# ATxmega256C3 device description
Architecture: AVR8_XMEGA; Family: AVR XMEGA
Registers are 8-bit, access not given, no defined reset value unless marked. A register's access mark holds for its fields unless they carry their own. Offsets are from the block's base; [hi:lo] are bit positions; {n}, {i} and the like mark numbered series; 'fields as' and 'values as' point back to an identical list.

## OSC — Oscillator
Instances: OSC 0x0050
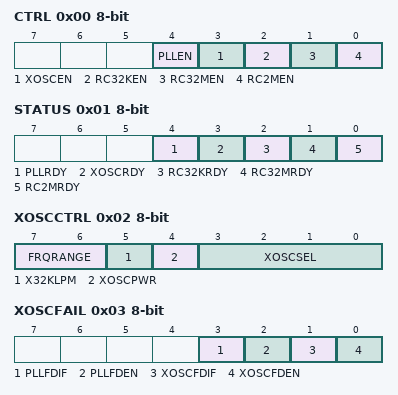
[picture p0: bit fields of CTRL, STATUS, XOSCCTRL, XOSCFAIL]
0x00 CTRL — Control Register
  [4] PLLEN — PLL Enable
  [3] XOSCEN — External Oscillator Enable
  [2] RC32KEN — Internal 32.768 kHz RC Oscillator Enable
  [1] RC32MEN — Internal 32 MHz RC Oscillator Enable
  [0] RC2MEN — Internal 2 MHz RC Oscillator Enable
0x01 STATUS
  [4] PLLRDY — PLL Ready
  [3] XOSCRDY — External Oscillator Ready
  [2] RC32KRDY — Internal 32.768 kHz RC Oscillator Ready
  [1] RC32MRDY — Internal 32 MHz RC Oscillator Ready
  [0] RC2MRDY — Internal 2 MHz RC Oscillator Ready
0x02 XOSCCTRL — External Oscillator Control Register
  [7:6] FRQRANGE — Frequency Range
    0=04TO2 (0.4 - 2 MHz); 1=2TO9 (2 - 9 MHz); 2=9TO12 (9 - 12 MHz); 3=12TO16 (12 - 16 MHz)
  [5] X32KLPM — 32.768 kHz XTAL OSC Low-power Mode
  [4] XOSCPWR — 16 MHz Crystal Oscillator High Power mode
  [3:0] XOSCSEL — External Oscillator Selection and Startup Time
    0=EXTCLK (External Clock - 6 CLK); 2=32KHz (32.768 kHz TOSC - 32K CLK); 3=XTAL_256CLK (0.4-16 MHz XTAL - 256 CLK); 7=XTAL_1KCLK (0.4-16 MHz XTAL - 1K CLK); 11=XTAL_16KCLK (0.4-16 MHz XTAL - 16K CLK)
0x03 XOSCFAIL — Oscillator Failure Detection Register
  [3] PLLFDIF — PLL Failure Detection Interrupt Flag
  [2] PLLFDEN — PLL Failure Detection Enable
  [1] XOSCFDIF — XOSC Failure Detection Interrupt Flag
  [0] XOSCFDEN — XOSC Failure Detection Enable
0x04 RC32KCAL — 32.768 kHz Internal Oscillator Calibration Register
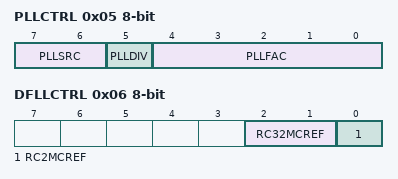
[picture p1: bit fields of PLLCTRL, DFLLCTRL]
0x05 PLLCTRL — PLL Control Register
  [7:6] PLLSRC — Clock Source
    0=RC2M (Internal 2 MHz RC Oscillator); 2=RC32M (Internal 32 MHz RC Oscillator); 3=XOSC (External Oscillator)
  [5] PLLDIV — Divide by 2
  [4:0] PLLFAC — Multiplication Factor
0x06 DFLLCTRL — DFLL Control Register
  [2:1] RC32MCREF — 32 MHz DFLL Calibration Reference
    0=RC32K (Internal 32.768 kHz RC Oscillator); 1=XOSC32K (External 32.768 kHz Crystal Oscillator); 2=USBSOF (USB Start of Frame)
  [0] RC2MCREF — 2 MHz DFLL Calibration Reference
    0=RC32K (Internal 32.768 kHz RC Oscillator); 1=XOSC32K (External 32.768 kHz Crystal Oscillator)

## DFLL
Instances: DFLLRC32M 0x0060, DFLLRC2M 0x0068
0x00 CTRL — Control Register
  [0] ENABLE — DFLL Enable
0x02 CALA — Calibration Register A
  [6:0] CALL — DFLL Calibration Value A
0x03 CALB — Calibration Register B
  [5:0] CALH — DFLL Calibration Value B
{0x4+i} COMP{i} (i=0..2) — Oscillator Compare Register {i}

## RST — Reset
Instances: RST 0x0078
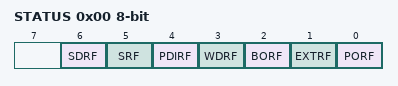
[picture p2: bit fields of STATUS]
0x00 STATUS
  [6] SDRF — Spike Detection Reset Flag
  [5] SRF — Software Reset Flag
  [4] PDIRF — Programming and Debug Interface Interface Reset Flag
  [3] WDRF — Watchdog Reset Flag
  [2] BORF — Brown-out Reset Flag
  [1] EXTRF — External Reset Flag
  [0] PORF — Power-on Reset Flag
0x01 CTRL — Control Register
  [0] SWRST — Software Reset

## WDT — Watch-Dog Timer
Instances: WDT 0x0080
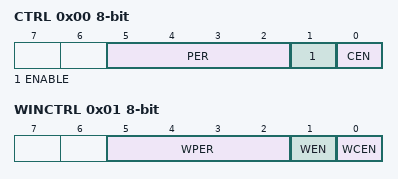
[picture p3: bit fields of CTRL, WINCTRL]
0x00 CTRL — Control
  [5:2] PER — Period
    0=8CLK (8 cycles (8ms @ 3.3V)); 1=16CLK (16 cycles (16ms @ 3.3V)); 2=32CLK (32 cycles (32ms @ 3.3V)); 3=64CLK (64 cycles (64ms @ 3.3V)); 4=128CLK (128 cycles (0.128s @ 3.3V)); 5=256CLK (256 cycles (0.256s @ 3.3V)); 6=512CLK (512 cycles (0.512s @ 3.3V)); 7=1KCLK (1K cycles (1s @ 3.3V)); 8=2KCLK (2K cycles (2s @ 3.3V)); 9=4KCLK (4K cycles (4s @ 3.3V)); 10=8KCLK (8K cycles (8s @ 3.3V))
  [1] ENABLE
  [0] CEN — Change Enable
0x01 WINCTRL — Windowed Mode Control
  [5:2] WPER — Windowed Mode Period
    values as CTRL.PER
  [1] WEN — Windowed Mode Enable
  [0] WCEN — Windowed Mode Change Enable
0x02 STATUS
  [0] SYNCBUSY — Syncronization busy

## MCU — MCU Control
Instances: MCU 0x0090
{0x0+i} DEVID{i} (i=0..2) — Device ID byte {i}
0x03 REVID — Revision ID
0x07 ANAINIT — Analog Startup Delay
  [1:0] STARTUPDLYA — Analog startup delay Port A
0x08 EVSYSLOCK — Event System Lock
  [0] EVSYS0LOCK — Event Channel 0-3 Lock
0x09 AWEXLOCK
  [0] AWEXCLOCK — AWeX on T/C C0 Lock
